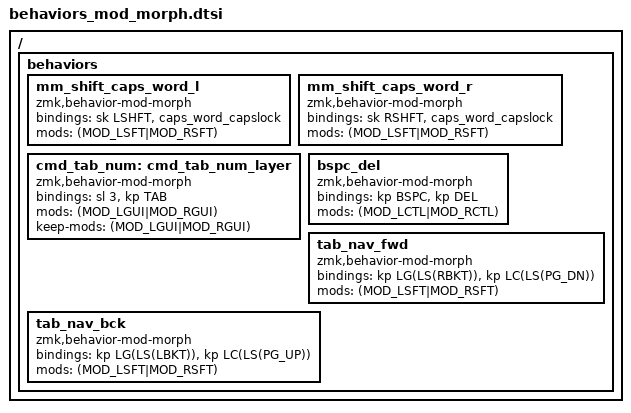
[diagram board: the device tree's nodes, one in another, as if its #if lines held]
/ {

    behaviors {

        /*
         * Sticky shift + Caps Word
         *
         * Usage: &mm_shift_caps_word_l or &mm_shift_caps_word_r
         * Tap: Sticky shift
         * HMR-Shift-Tap: Caps Word
         * Double Tap: Caps Word
         *   - The first tap activates sticky shift mod
         *   - The second tap is now a shift + press, which activates
         *     the mod morph
         * Hold: Shift
         *
         * Credits to urob for this genius combo.
         */
        mm_shift_caps_word_l: mm_shift_caps_word_l {
            compatible = "zmk,behavior-mod-morph";
            #binding-cells = <0>;

            #ifdef HAS_CAPSLOCK
                bindings = <&sk LSHFT>, <&caps_word_capslock>;
            #else
                bindings = <&sk LSHFT>, <&caps_word>;
            #endif

            mods = <(MOD_LSFT|MOD_RSFT)>;
        };

        mm_shift_caps_word_r: mm_shift_caps_word_r {
            compatible = "zmk,behavior-mod-morph";
            #binding-cells = <0>;

            #ifdef HAS_CAPSLOCK
                bindings = <&sk RSHFT>, <&caps_word_capslock>;
            #else
                bindings = <&sk RSHFT>, <&caps_word>;
            #endif

            mods = <(MOD_LSFT|MOD_RSFT)>;
        };

        cmd_tab_num: cmd_tab_num_layer {
            compatible = "zmk,behavior-mod-morph";
            #binding-cells = <0>;
            bindings = <&sl 3>, <&kp TAB>;
            mods = <(MOD_LGUI|MOD_RGUI)>;
            keep-mods = <(MOD_LGUI|MOD_RGUI)>;
        };
        
        bspc_del: bspc_del {
            compatible = "zmk,behavior-mod-morph";
            #binding-cells = <0>;
            bindings = <&kp BSPC>, <&kp DEL>;
            mods = <(MOD_LCTL|MOD_RCTL)>;
        };

        tab_nav_fwd: tab_nav_fwd {
            compatible = "zmk,behavior-mod-morph";
            #binding-cells = <0>;
            bindings = <&kp LG(LS(RBKT))>, <&kp LC(LS(PG_DN))>;
            mods = <(MOD_LSFT|MOD_RSFT)>;
        };

        tab_nav_bck: tab_nav_bck {
            compatible = "zmk,behavior-mod-morph";
            #binding-cells = <0>;
            bindings = <&kp LG(LS(LBKT))>, <&kp LC(LS(PG_UP))>;
            mods = <(MOD_LSFT|MOD_RSFT)>;
        };
    };
};
